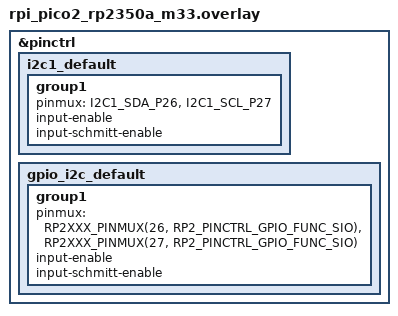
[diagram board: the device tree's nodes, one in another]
#include <zephyr/dt-bindings/pinctrl/rpi-pico-rp2350a-pinctrl.h>

&pinctrl {
    i2c1_default: i2c1_default {
        group1 {
            pinmux = <I2C1_SDA_P26>, <I2C1_SCL_P27>;
            input-enable;
            input-schmitt-enable;
        };
    };

    gpio_i2c_default: gpio_i2c_default {
        group1 {
            pinmux = <RP2XXX_PINMUX(26, RP2_PINCTRL_GPIO_FUNC_SIO)>,
                     <RP2XXX_PINMUX(27, RP2_PINCTRL_GPIO_FUNC_SIO)>;
            input-enable;
            input-schmitt-enable;
        };
    };
};
